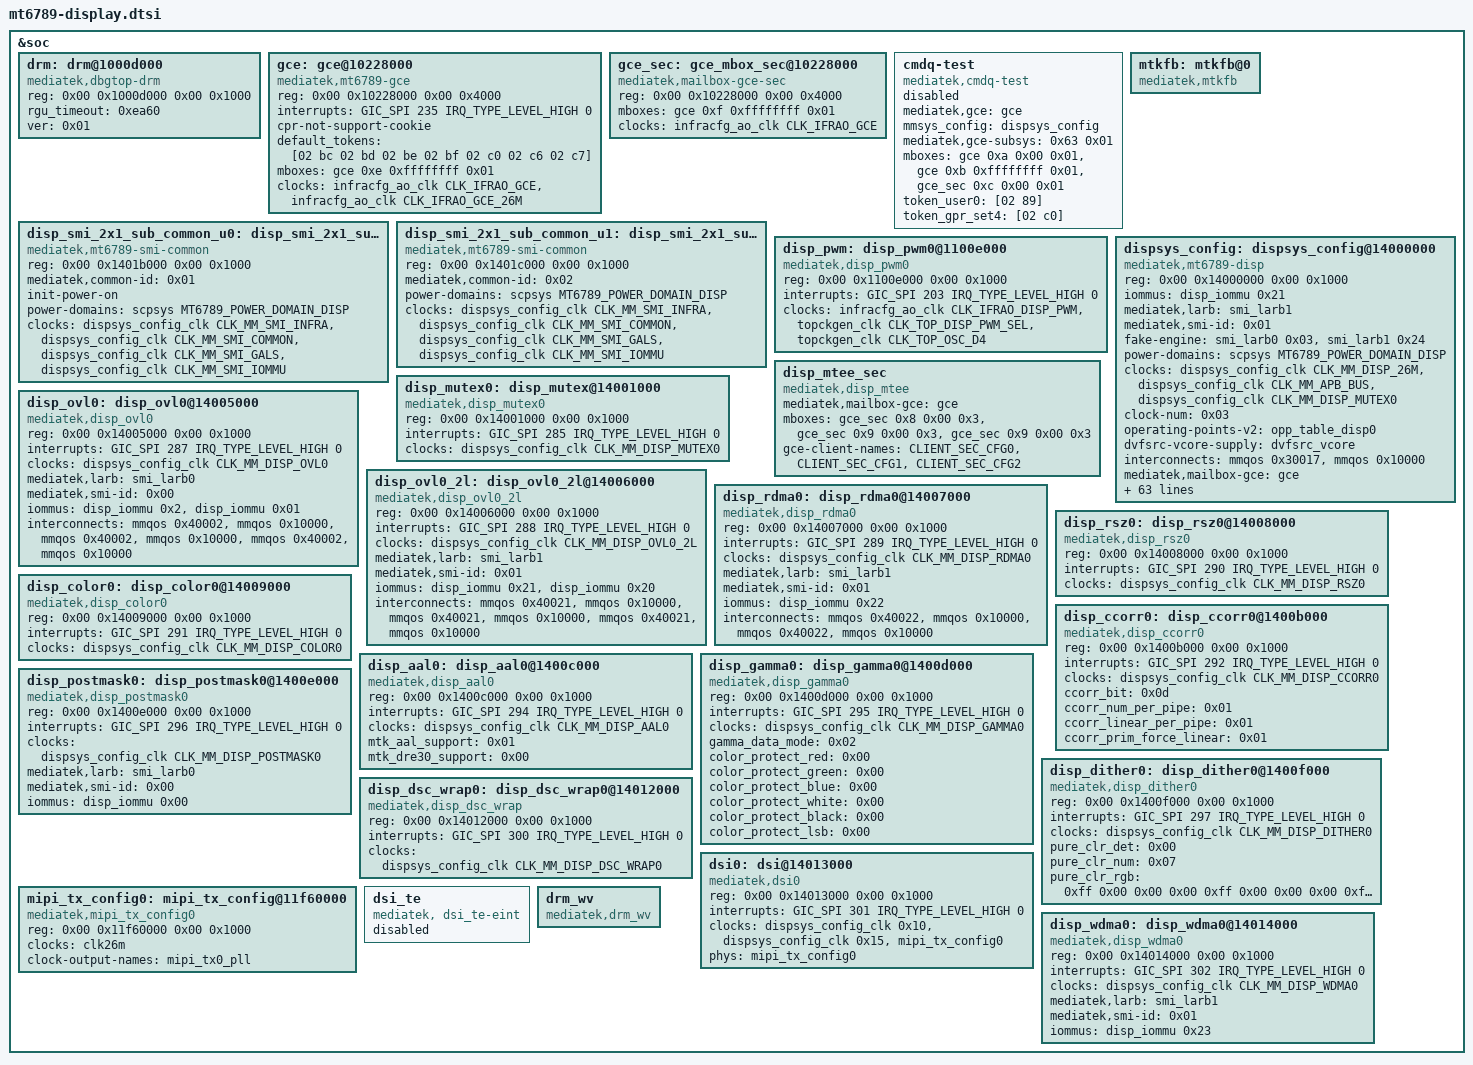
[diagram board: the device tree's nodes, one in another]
// SPDX-License-Identifier: (GPL-2.0 OR MIT)
/* MT6789 display blocks - split out of the soc node by tools/scripts/dts-socsplit.py */

&soc {
	drm: drm@1000d000 {
		compatible = "mediatek,dbgtop-drm";
		reg = <0x00 0x1000d000 0x00 0x1000>;
		rgu_timeout = <0xea60>;
		ver = <0x01>;
	};

	gce: gce@10228000 {
		compatible = "mediatek,mt6789-gce";
		reg = <0x00 0x10228000 0x00 0x4000>;
		interrupts = <GIC_SPI 235 IRQ_TYPE_LEVEL_HIGH 0>;
		#mbox-cells = <0x03>;
		#gce-event-cells = <0x01>;
		#gce-subsys-cells = <0x02>;
		cpr-not-support-cookie;
		default_tokens = [02 bc 02 bd 02 be 02 bf 02 c0 02 c6 02 c7];
		mboxes = <&gce 0xe 0xffffffff 0x01>;
		clocks = <&infracfg_ao_clk CLK_IFRAO_GCE &infracfg_ao_clk CLK_IFRAO_GCE_26M>;
		clock-names = "gce", "gce-timer";
	};

	gce_sec: gce_mbox_sec@10228000 {
		compatible = "mediatek,mailbox-gce-sec";
		reg = <0x00 0x10228000 0x00 0x4000>;
		#mbox-cells = <0x03>;
		mboxes = <&gce 0xf 0xffffffff 0x01>;
		clocks = <&infracfg_ao_clk CLK_IFRAO_GCE>;
		clock-names = "gce";
	};

	cmdq-test {
		compatible = "mediatek,cmdq-test";
		mediatek,gce = <&gce>;
		mmsys_config = <&dispsys_config>;
		mediatek,gce-subsys = <0x63 0x01>;
		mboxes = <&gce 0xa 0x00 0x01 &gce 0xb 0xffffffff 0x01 &gce_sec 0xc 0x00 0x01>;
		token_user0 = [02 89];
		token_gpr_set4 = [02 c0];
		status = "disabled";
	};

	disp_smi_2x1_sub_common_u0: disp_smi_2x1_sub_comm0@1401b000 {
		compatible = "mediatek,mt6789-smi-common", "mediatek,smi-common", "syscon", "mediatek,smi-sub-common";
		reg = <0x00 0x1401b000 0x00 0x1000>;
		mediatek,common-id = <0x01>;
		init-power-on;
		power-domains = <&scpsys MT6789_POWER_DOMAIN_DISP>;
		clocks = <&dispsys_config_clk CLK_MM_SMI_INFRA &dispsys_config_clk CLK_MM_SMI_COMMON &dispsys_config_clk CLK_MM_SMI_GALS &dispsys_config_clk CLK_MM_SMI_IOMMU>;
		clock-names = "apb", "smi", "gals0", "gals1";
	};

	disp_smi_2x1_sub_common_u1: disp_smi_2x1_sub_comm1@1401c000 {
		compatible = "mediatek,mt6789-smi-common", "mediatek,smi-common", "syscon", "mediatek,smi-sub-common";
		reg = <0x00 0x1401c000 0x00 0x1000>;
		mediatek,common-id = <0x02>;
		power-domains = <&scpsys MT6789_POWER_DOMAIN_DISP>;
		clocks = <&dispsys_config_clk CLK_MM_SMI_INFRA &dispsys_config_clk CLK_MM_SMI_COMMON &dispsys_config_clk CLK_MM_SMI_GALS &dispsys_config_clk CLK_MM_SMI_IOMMU>;
		clock-names = "apb", "smi", "gals0", "gals1";
	};

	mtkfb: mtkfb@0 {
		compatible = "mediatek,mtkfb";
	};

	disp_pwm: disp_pwm0@1100e000 {
		compatible = "mediatek,disp_pwm0", "mediatek,mt6789-disp-pwm";
		reg = <0x00 0x1100e000 0x00 0x1000>;
		interrupts = <GIC_SPI 203 IRQ_TYPE_LEVEL_HIGH 0>;
		#pwm-cells = <0x02>;
		clocks = <&infracfg_ao_clk CLK_IFRAO_DISP_PWM &topckgen_clk CLK_TOP_DISP_PWM_SEL &topckgen_clk CLK_TOP_OSC_D4>;
		clock-names = "main", "mm", "pwm_src";
	};

	dispsys_config: dispsys_config@14000000 {
		compatible = "mediatek,mt6789-disp";
		reg = <0x00 0x14000000 0x00 0x1000>;
		#clock-cells = <0x01>;
		iommus = <&disp_iommu 0x21>;
		mediatek,larb = <&smi_larb1>;
		mediatek,smi-id = <0x01>;
		fake-engine = <&smi_larb0 0x03 &smi_larb1 0x24>;
		power-domains = <&scpsys MT6789_POWER_DOMAIN_DISP>;
		clocks = <&dispsys_config_clk CLK_MM_DISP_26M &dispsys_config_clk CLK_MM_APB_BUS &dispsys_config_clk CLK_MM_DISP_MUTEX0>;
		clock-num = <0x03>;
		operating-points-v2 = <&opp_table_disp0>;
		dvfsrc-vcore-supply = <&dvfsrc_vcore>;
		interconnects = <&mmqos 0x30017 &mmqos 0x10000>;
		interconnect-names = "disp_hrt_qos";
		mediatek,mailbox-gce = <&gce>;
		mboxes = <&gce 0x00 0x00 0x4 &gce 0x01 0x00 0x4 &gce 0x2 0x00 0x4 &gce 0x3 0xffffffff 0x2 &gce 0x4 0x00 0x4 &gce 0x6 0x00 0x3>;
		gce-client-names = "CLIENT_CFG0", "CLIENT_CFG1", "CLIENT_CFG2", "CLIENT_TRIG_LOOP0", "CLIENT_SUB_CFG0", "CLIENT_DSI_CFG0";
		gce-subsys = <&gce 0x14000000 0x01 &gce 0x14010000 0x02 &gce 0x14020000 0x03>;
		gce-event-names = "disp_mutex0_eof", "disp_token_stream_dirty0", "disp_wait_dsi0_te", "disp_token_stream_eof0", "disp_dsi0_eof", "disp_token_esd_eof0", "disp_rdma0_eof0", "disp_wdma0_eof0", "disp_token_stream_block0", "disp_token_cabc_eof0", "disp_wdma0_eof2", "disp_dsi0_sof0", "disp_token_disp_va_start0", "disp_token_disp_va_end0", "disp_token_disp_va_start2", "disp_token_disp_va_end2";
		gce-events = <&gce 0x1b2 &gce 0x280 &gce 0x1c2 &gce 0x281 &gce 0x19a &gce 0x282 &gce 0x19e &gce 0x19b &gce 0x283 &gce 0x284 &gce 0x19b &gce 0x18e &gce 0x2b4 &gce 0x2b5 &gce 0x2b4 &gce 0x2b5>;
		helper-name = "MTK_DRM_OPT_STAGE", "MTK_DRM_OPT_USE_CMDQ", "MTK_DRM_OPT_USE_M4U", "MTK_DRM_OPT_MMQOS_SUPPORT", "MTK_DRM_OPT_MMDVFS_SUPPORT", "MTK_DRM_OPT_SODI_SUPPORT", "MTK_DRM_OPT_IDLE_MGR", "MTK_DRM_OPT_IDLEMGR_SWTCH_DECOUPLE", "MTK_DRM_OPT_IDLEMGR_BY_REPAINT", "MTK_DRM_OPT_IDLEMGR_ENTER_ULPS", "MTK_DRM_OPT_IDLEMGR_KEEP_LP11", "MTK_DRM_OPT_DYNAMIC_RDMA_GOLDEN_SETTING", "MTK_DRM_OPT_IDLEMGR_DISABLE_ROUTINE_IRQ", "MTK_DRM_OPT_MET_LOG", "MTK_DRM_OPT_USE_PQ", "MTK_DRM_OPT_ESD_CHECK_RECOVERY", "MTK_DRM_OPT_ESD_CHECK_SWITCH", "MTK_DRM_OPT_PRESENT_FENCE", "MTK_DRM_OPT_RDMA_UNDERFLOW_AEE", "MTK_DRM_OPT_DSI_UNDERRUN_AEE", "MTK_DRM_OPT_HRT", "MTK_DRM_OPT_HRT_MODE", "MTK_DRM_OPT_DELAYED_TRIGGER", "MTK_DRM_OPT_OVL_EXT_LAYER", "MTK_DRM_OPT_AOD", "MTK_DRM_OPT_RPO", "MTK_DRM_OPT_DUAL_PIPE", "MTK_DRM_OPT_DC_BY_HRT", "MTK_DRM_OPT_OVL_WCG", "MTK_DRM_OPT_OVL_SBCH", "MTK_DRM_OPT_COMMIT_NO_WAIT_VBLANK", "MTK_DRM_OPT_MET", "MTK_DRM_OPT_REG_PARSER_RAW_DUMP", "MTK_DRM_OPT_VP_PQ", "MTK_DRM_OPT_GAME_PQ", "MTK_DRM_OPT_MMPATH", "MTK_DRM_OPT_HBM", "MTK_DRM_OPT_VDS_PATH_SWITCH", "MTK_DRM_OPT_LAYER_REC", "MTK_DRM_OPT_CLEAR_LAYER", "MTK_DRM_OPT_LFR", "MTK_DRM_OPT_SF_PF", "MTK_DRM_OPT_DYN_MIPI_CHANGE", "MTK_DRM_OPT_PRIM_DUAL_PIPE", "MTK_DRM_OPT_MSYNC2_0", "MTK_DRM_OPT_VIRTUAL_DISP", "MTK_DRM_OPT_MML_PRIMARY";
		helper-value = <0x00 0x01 0x01 0x01 0x01 0x00 0x01 0x00 0x00 0x00 0x00 0x00 0x01 0x00 0x01 0x01 0x01 0x01 0x00 0x01 0x01 0x01 0x00 0x01 0x00 0x01 0x00 0x00 0x00 0x00 0x01 0x00 0x00 0x00 0x00 0x00 0x00 0x00 0x00 0x01 0x01 0x00 0x01 0x00 0x00 0x00 0x00>;
	};

	disp_mtee_sec: disp_mtee_sec {
		compatible = "mediatek,disp_mtee";
		mediatek,mailbox-gce = <&gce>;
		mboxes = <&gce_sec 0x8 0x00 0x3 &gce_sec 0x9 0x00 0x3 &gce_sec 0x9 0x00 0x3>;
		gce-client-names = "CLIENT_SEC_CFG0", "CLIENT_SEC_CFG1", "CLIENT_SEC_CFG2";
	};

	disp_mutex0: disp_mutex@14001000 {
		compatible = "mediatek,disp_mutex0", "mediatek,mt6789-disp-mutex";
		reg = <0x00 0x14001000 0x00 0x1000>;
		interrupts = <GIC_SPI 285 IRQ_TYPE_LEVEL_HIGH 0>;
		clocks = <&dispsys_config_clk CLK_MM_DISP_MUTEX0>;
	};

	disp_ovl0: disp_ovl0@14005000 {
		compatible = "mediatek,disp_ovl0", "mediatek,mt6789-disp-ovl";
		reg = <0x00 0x14005000 0x00 0x1000>;
		interrupts = <GIC_SPI 287 IRQ_TYPE_LEVEL_HIGH 0>;
		clocks = <&dispsys_config_clk CLK_MM_DISP_OVL0>;
		mediatek,larb = <&smi_larb0>;
		mediatek,smi-id = <0x00>;
		iommus = <&disp_iommu 0x2 &disp_iommu 0x01>;
		interconnects = <&mmqos 0x40002 &mmqos 0x10000 &mmqos 0x40002 &mmqos 0x10000 &mmqos 0x40002 &mmqos 0x10000>;
		interconnect-names = "DDP_COMPONENT_OVL0_qos", "DDP_COMPONENT_OVL0_fbdc_qos", "DDP_COMPONENT_OVL0_hrt_qos";
	};

	disp_ovl0_2l: disp_ovl0_2l@14006000 {
		compatible = "mediatek,disp_ovl0_2l", "mediatek,mt6789-disp-ovl";
		reg = <0x00 0x14006000 0x00 0x1000>;
		interrupts = <GIC_SPI 288 IRQ_TYPE_LEVEL_HIGH 0>;
		clocks = <&dispsys_config_clk CLK_MM_DISP_OVL0_2L>;
		mediatek,larb = <&smi_larb1>;
		mediatek,smi-id = <0x01>;
		iommus = <&disp_iommu 0x21 &disp_iommu 0x20>;
		interconnects = <&mmqos 0x40021 &mmqos 0x10000 &mmqos 0x40021 &mmqos 0x10000 &mmqos 0x40021 &mmqos 0x10000>;
		interconnect-names = "DDP_COMPONENT_OVL0_2L_qos", "DDP_COMPONENT_OVL0_2L_fbdc_qos", "DDP_COMPONENT_OVL0_2L_hrt_qos";
	};

	disp_rdma0: disp_rdma0@14007000 {
		compatible = "mediatek,disp_rdma0", "mediatek,mt6789-disp-rdma";
		reg = <0x00 0x14007000 0x00 0x1000>;
		interrupts = <GIC_SPI 289 IRQ_TYPE_LEVEL_HIGH 0>;
		clocks = <&dispsys_config_clk CLK_MM_DISP_RDMA0>;
		mediatek,larb = <&smi_larb1>;
		mediatek,smi-id = <0x01>;
		iommus = <&disp_iommu 0x22>;
		interconnects = <&mmqos 0x40022 &mmqos 0x10000 &mmqos 0x40022 &mmqos 0x10000>;
		interconnect-names = "DDP_COMPONENT_RDMA0_qos", "DDP_COMPONENT_RDMA0_hrt_qos";
	};

	disp_rsz0: disp_rsz0@14008000 {
		compatible = "mediatek,disp_rsz0", "mediatek,mt6789-disp-rsz";
		reg = <0x00 0x14008000 0x00 0x1000>;
		interrupts = <GIC_SPI 290 IRQ_TYPE_LEVEL_HIGH 0>;
		clocks = <&dispsys_config_clk CLK_MM_DISP_RSZ0>;
	};

	disp_color0: disp_color0@14009000 {
		compatible = "mediatek,disp_color0", "mediatek,mt6789-disp-color";
		reg = <0x00 0x14009000 0x00 0x1000>;
		interrupts = <GIC_SPI 291 IRQ_TYPE_LEVEL_HIGH 0>;
		clocks = <&dispsys_config_clk CLK_MM_DISP_COLOR0>;
	};

	disp_ccorr0: disp_ccorr0@1400b000 {
		compatible = "mediatek,disp_ccorr0", "mediatek,mt6789-disp-ccorr";
		reg = <0x00 0x1400b000 0x00 0x1000>;
		interrupts = <GIC_SPI 292 IRQ_TYPE_LEVEL_HIGH 0>;
		clocks = <&dispsys_config_clk CLK_MM_DISP_CCORR0>;
		ccorr_bit = <0x0d>;
		ccorr_num_per_pipe = <0x01>;
		ccorr_linear_per_pipe = <0x01>;
		ccorr_prim_force_linear = <0x01>;
	};

	disp_aal0: disp_aal0@1400c000 {
		compatible = "mediatek,disp_aal0", "mediatek,mt6789-disp-aal";
		reg = <0x00 0x1400c000 0x00 0x1000>;
		interrupts = <GIC_SPI 294 IRQ_TYPE_LEVEL_HIGH 0>;
		clocks = <&dispsys_config_clk CLK_MM_DISP_AAL0>;
		mtk_aal_support = <0x01>;
		mtk_dre30_support = <0x00>;
	};

	disp_gamma0: disp_gamma0@1400d000 {
		compatible = "mediatek,disp_gamma0", "mediatek,mt6789-disp-gamma";
		reg = <0x00 0x1400d000 0x00 0x1000>;
		interrupts = <GIC_SPI 295 IRQ_TYPE_LEVEL_HIGH 0>;
		clocks = <&dispsys_config_clk CLK_MM_DISP_GAMMA0>;
		gamma_data_mode = <0x02>;
		color_protect_red = <0x00>;
		color_protect_green = <0x00>;
		color_protect_blue = <0x00>;
		color_protect_white = <0x00>;
		color_protect_black = <0x00>;
		color_protect_lsb = <0x00>;
	};

	disp_postmask0: disp_postmask0@1400e000 {
		compatible = "mediatek,disp_postmask0", "mediatek,mt6789-disp-postmask";
		reg = <0x00 0x1400e000 0x00 0x1000>;
		interrupts = <GIC_SPI 296 IRQ_TYPE_LEVEL_HIGH 0>;
		clocks = <&dispsys_config_clk CLK_MM_DISP_POSTMASK0>;
		mediatek,larb = <&smi_larb0>;
		mediatek,smi-id = <0x00>;
		iommus = <&disp_iommu 0x00>;
	};

	disp_dither0: disp_dither0@1400f000 {
		compatible = "mediatek,disp_dither0", "mediatek,mt6789-disp-dither";
		reg = <0x00 0x1400f000 0x00 0x1000>;
		interrupts = <GIC_SPI 297 IRQ_TYPE_LEVEL_HIGH 0>;
		clocks = <&dispsys_config_clk CLK_MM_DISP_DITHER0>;
		pure_clr_det = <0x00>;
		pure_clr_num = <0x07>;
		pure_clr_rgb = <0xff 0x00 0x00 0x00 0xff 0x00 0x00 0x00 0xff 0xff 0xff 0x00 0xff 0x00 0xff 0x00 0xff 0xff 0xff 0xff 0xff>;
	};

	disp_dsc_wrap0: disp_dsc_wrap0@14012000 {
		compatible = "mediatek,disp_dsc_wrap", "mediatek,mt6789-disp-dsc";
		reg = <0x00 0x14012000 0x00 0x1000>;
		interrupts = <GIC_SPI 300 IRQ_TYPE_LEVEL_HIGH 0>;
		clocks = <&dispsys_config_clk CLK_MM_DISP_DSC_WRAP0>;
	};

	mipi_tx_config0: mipi_tx_config@11f60000 {
		compatible = "mediatek,mipi_tx_config0", "mediatek,mt6789-mipi-tx";
		reg = <0x00 0x11f60000 0x00 0x1000>;
		clocks = <&clk26m>;
		#clock-cells = <0x00>;
		#phy-cells = <0x00>;
		clock-output-names = "mipi_tx0_pll";
	};

	dsi0: dsi@14013000 {
		compatible = "mediatek,dsi0", "mediatek,mt6789-dsi";
		reg = <0x00 0x14013000 0x00 0x1000>;
		interrupts = <GIC_SPI 301 IRQ_TYPE_LEVEL_HIGH 0>;
		clocks = <&dispsys_config_clk 0x10 &dispsys_config_clk 0x15 &mipi_tx_config0>;
		clock-names = "engine", "digital", "hs";
		phys = <&mipi_tx_config0>;
		phy-names = "dphy";
	};

	dsi_te: dsi_te {
		compatible = "mediatek, dsi_te-eint";
		status = "disabled";
	};

	disp_wdma0: disp_wdma0@14014000 {
		compatible = "mediatek,disp_wdma0", "mediatek,mt6789-disp-wdma";
		reg = <0x00 0x14014000 0x00 0x1000>;
		interrupts = <GIC_SPI 302 IRQ_TYPE_LEVEL_HIGH 0>;
		clocks = <&dispsys_config_clk CLK_MM_DISP_WDMA0>;
		mediatek,larb = <&smi_larb1>;
		mediatek,smi-id = <0x01>;
		iommus = <&disp_iommu 0x23>;
	};

	drm_wv: drm_wv {
		compatible = "mediatek,drm_wv";
		status = "okay";
	};

};
